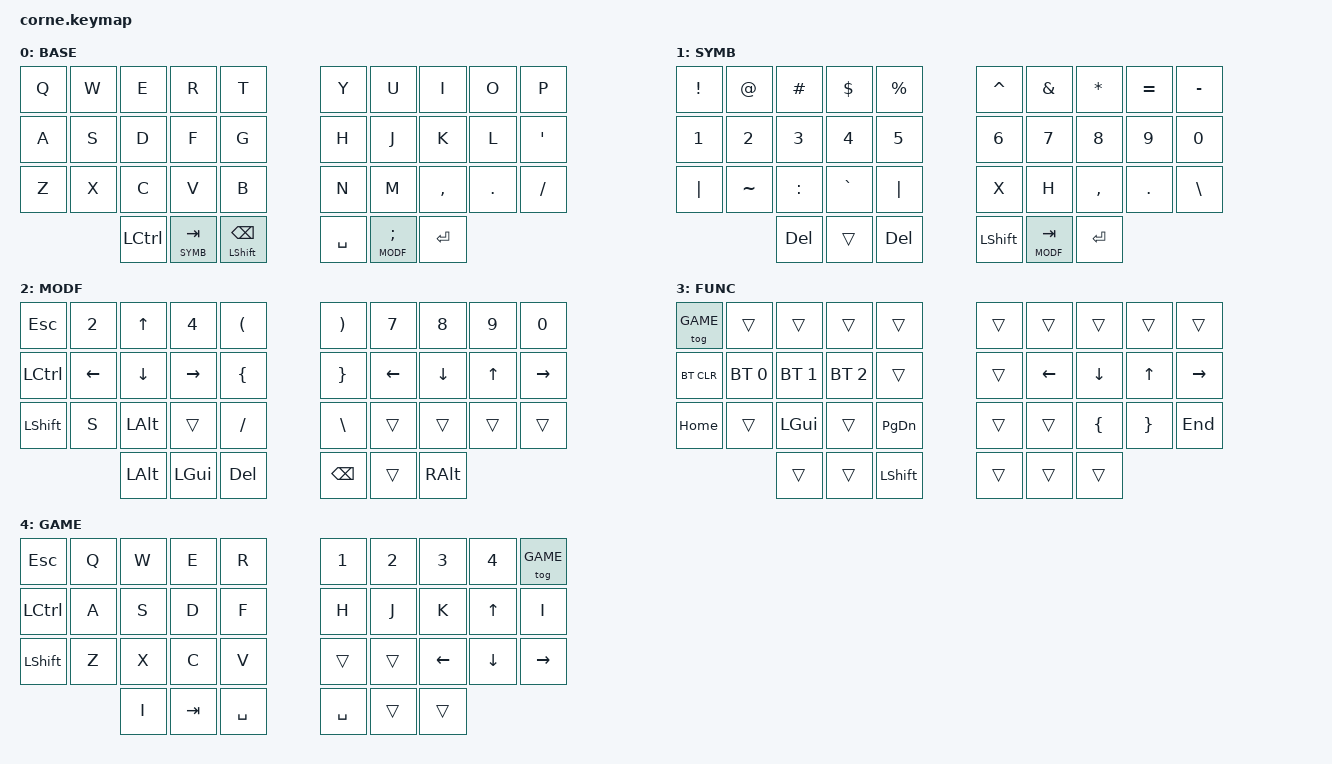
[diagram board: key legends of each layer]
/*
 * Copyright (c) 2020 The ZMK Contributors
 *
 * SPDX-License-Identifier: MIT
 */

#include <behaviors.dtsi>
#include <dt-bindings/zmk/keys.h>
#include <dt-bindings/zmk/bt.h>
#include <dt-bindings/zmk/outputs.h>
#include <dt-bindings/zmk/ext_power.h>

#define COMBO_TIMEOUT 60
#define FAST_COMBO_TIMEOUT 30
#define VERY_FAST_COMBO_TIMEOUT 20

// Cleaning up long code segments
#define COMBO(NAME, KEYS, MAPPING, LAYERS, DELAY) combo_ ## NAME { \
            timeout-ms = <DELAY>; \
            key-positions = <KEYS>; \
            bindings = <MAPPING>; \
            layers = <LAYERS>; \
        };

#define MOD_MORPH(NAME, KEY1, KEY2) NAME: NAME { \
            compatible = "zmk,behavior-mod-morph"; \
            label = # NAME; \
            #binding-cells = <0>; \
            bindings = <KEY1>, <KEY2>; \
            mods = <(MOD_LSFT|MOD_RSFT)>; \
        };
#define MACRO(NAME, ...) ZMK_MACRO(NAME, \
  wait-ms = <10>; \
  tap-ms = <10>; \
  bindings = __VA_ARGS__;)
#define PRESS(KEY) <&macro_press KEY>
#define RELEASE(KEY) <&macro_release KEY>
#define TAP(KEY) <&macro_tap KEY>

// layers
#define BASE   0
#define SYMB 1
#define MODF 2
#define FUNC 3
#define GAME 4

&mt {
  compatible = "zmk,behavior-hold-tap";
  tapping-term-ms = <200>;
  quick_tap_ms = <200>;
  flavor = "balanced";
};

&lt {
  compatible = "zmk,behavior-hold-tap";
  tapping-term-ms = <110>;
  quick_tap_ms = <200>;
  flavor = "balanced";
};

/ {
  chosen {
    zmk,matrix_transform = &five_column_transform;
  };
};
/ {
    conditional_layers {
        compatible = "zmk,conditional-layers";
        tri_layer {
            if-layers = <1 2>;
            then-layer = <3>;
        };
    };
};
/ {
    macros {
      
    };
};
/ {
    combos {
        compatible = "zmk,combos";

    };
};
/ {
  keymap {
   compatible = "zmk,keymap";    
    base_layer {
      label = "BASE";
      // -----------------------------------------------------------------
      // |  Q  |  W  |  E  |  R       |  T  |   |  Y  |  U   |  I  |  O  |  P  |
      // |  A  |  S  |  D  |  F       |  G  |   |  H  |  J   |  K  |  L  |  '  |
      // |  Z  |  X  |  C  |  V       |  B  |   |  N  |  M   |  ,  |  .  |  /  |
      //             | ESC | LWR(TAB) | BKSP|   | SPC |RSE(;)| RET |
      bindings = <
        &kp Q   &kp W      &kp E      &kp R         &kp T            &kp Y          &kp U          &kp I       &kp O      &kp P     
        &kp A   &kp S      &kp D      &kp F         &kp G            &kp H          &kp J          &kp K       &kp L      &kp SQT 
        &kp Z   &kp X      &kp C      &kp V         &kp B            &kp N          &kp M          &kp COMMA   &kp DOT    &kp FSLH    
                           &kp LCTRL  &lt SYMB TAB &mt LSHFT BKSP   &kp SPACE      &lt MODF SEMI &kp RET
      >;
    };
    
    symb_layer {
      label = "SYMB";
      // -----------------------------------------------------------------
      // |  !  |  @  |  #  |  $  |  %  |   |  %  |  &  |  *  |  =  |  -  |
      // |  1  |  2  |  3  |  4  |  5  |   |  6  |  7  |  8  |  9  |  0  |
      // |  |  |  ~  |  :  |  `  |  |  |   |  x  |  h  |  ,  |  .  |  \  |
      //             | DEL |TRANS| DEL |   | BKSP| SPC | RET |
      bindings = <
        &kp EXCL  &kp AT    &kp HASH  &kp DLLR  &kp PRCNT  &kp CARET &kp AMPS      &kp STAR  &kp EQUAL&kp MINUS 
        &kp N1    &kp N2    &kp N3    &kp N4    &kp N5     &kp N6    &kp N7        &kp N8    &kp N9   &kp N0   
        &kp PIPE  &kp TILDE &kp COLON &kp GRAVE &kp PIPE   &kp X     &kp H         &kp COMMA &kp DOT  &kp BSLH 
                            &kp DEL   &trans    &kp DEL    &kp LSHFT &lt MODF TAB &kp RET
      >;
    };

    modf_layer {
      label = "MODF";
      // ------------------------------------------------------------------------
// | ESC |  2  |  UP |  4  |  (  |   |  )  |  7  |  8  |  9  |  0  | 
// | TAB | LFT | DWN | RGT |  {  |   |  }  | LFT | DWN |  UP | RGT |
// |LCTRL|  S  |     |     |  /  |   |  \  |     |     |     |     |
//             |LALT |LGUI | DEL |   | BKSP|     |RALT |
      bindings = <
   &kp ESC      &kp N2       &kp UP       &kp N4       &kp LPAR     &kp RPAR       &kp N7   &kp N8   &kp N9 &kp N0 
   &kp LCTRL      &kp LEFT     &kp DOWN     &kp RIGHT    &kp LBRC     &kp RBRC       &kp LEFT &kp DOWN &kp UP &kp RIGHT 
   &kp LSHFT    &kp S        &kp LALT       &trans       &kp FSLH     &kp BSLH       &trans   &trans   &trans &trans
                             &kp LALT     &kp LGUI     &kp DEL      &kp BKSP       &trans   &kp RALT
      >;
    };

    funct_layer {
      label = "FUNC";
      // ------------------------------------------------------------------------
      // | INS  | BACK |  UP  |  FWD | PGUP |   | BRI+ |  VOL+ | (  |  )  | DEL |
      // | BTCLR| BT1 | BT2 | BT3 | BT4 | BT5 |   | LFT | DWN |  UP | RGT |     |      |
      // | HOME | Z IN | LGUI | ZOUT | PGDN |   | BRI- |  VOL- | {  |  }  | END |
      //                              |   |   | SHIFT |  |   |
      bindings = <
        &tog GAME     &trans       &trans       &trans       &trans    &trans   &trans   &trans   &trans   &trans  
        &bt BT_CLR &bt BT_SEL 0 &bt BT_SEL 1 &bt BT_SEL 2 &trans    &trans   &kp LEFT &kp DOWN &kp UP   &kp RIGHT 
        &kp HOME   &trans       &kp LGUI     &trans       &kp PG_DN &trans   &trans   &kp LBRC &kp RBRC &kp END  
                                &trans       &trans       &kp LSHFT &trans   &trans   &trans
      >;
    };

    game_layer {
      label = "GAME";
      // ------------------------------------------------------------------------
      // | INS  | BACK |  UP  |  FWD | PGUP |   | BRI+ |  VOL+ | (  |  )  | DEL |
      // | BTCLR| BT1 | BT2 | BT3 | BT4 | BT5 |   | LFT | DWN |  UP | RGT |     |      |
      // | HOME | Z IN | LGUI | ZOUT | PGDN |   | BRI- |  VOL- | {  |  }  | END |
      //                              |   |   | SHIFT |  |   |
      bindings = <
        &kp ESC   &kp Q &kp W      &kp E        &kp R    &kp N1   &kp N2 &kp N3 &kp N4   &tog GAME  
        &kp LCTRL &kp A &kp S      &kp D        &kp F    &kp H   &kp J &kp K &kp UP   &kp I 
        &kp LSHFT &kp Z &kp X      &kp C        &kp V    &trans   &trans   &kp LEFT &kp DOWN &kp RIGHT  
                        &kp I &kp TAB &kp SPACE &kp SPACE   &trans   &trans
      >;
    };
  };
};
